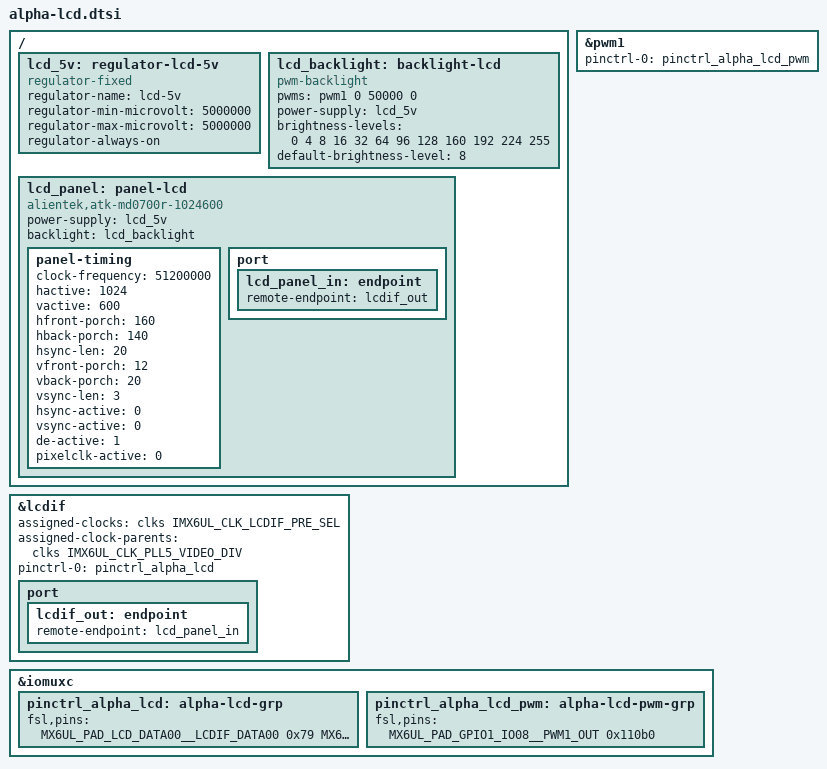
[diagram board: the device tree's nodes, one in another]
// SPDX-License-Identifier: GPL-2.0-or-later
/* ALPHA V2.4 + ATK-MD0700R-1024600, 24-bit RGB, DE mode. */
/ {
	lcd_5v: regulator-lcd-5v {
		compatible = "regulator-fixed";
		regulator-name = "lcd-5v";
		regulator-min-microvolt = <5000000>;
		regulator-max-microvolt = <5000000>;
		regulator-always-on;
	};

	lcd_backlight: backlight-lcd {
		compatible = "pwm-backlight";
		pwms = <&pwm1 0 50000 0>; /* 20 kHz, active high */
		power-supply = <&lcd_5v>;
		brightness-levels = <0 4 8 16 32 64 96 128 160 192 224 255>;
		default-brightness-level = <8>;
	};

	lcd_panel: panel-lcd {
		compatible = "alientek,atk-md0700r-1024600", "panel-dpi";
		power-supply = <&lcd_5v>;
		backlight = <&lcd_backlight>;
		/* Pin 40 is board RESET, not a separately controllable GPIO. */
		panel-timing {
			clock-frequency = <51200000>;
			hactive = <1024>;
			vactive = <600>;
			/* DE blanking totals: 320 pixels, 35 lines. */
			hfront-porch = <160>;
			hback-porch = <140>;
			hsync-len = <20>;
			vfront-porch = <12>;
			vback-porch = <20>;
			vsync-len = <3>;
			hsync-active = <0>;
			vsync-active = <0>;
			de-active = <1>;
			/* Drive on falling edge, panel samples rising edge. */
			pixelclk-active = <0>;
		};
		port {
			lcd_panel_in: endpoint {
				remote-endpoint = <&lcdif_out>;
			};
		};
	};
};

&lcdif {
	assigned-clocks = <&clks IMX6UL_CLK_LCDIF_PRE_SEL>;
	assigned-clock-parents = <&clks IMX6UL_CLK_PLL5_VIDEO_DIV>;
	pinctrl-names = "default";
	pinctrl-0 = <&pinctrl_alpha_lcd>;
	status = "okay";
	port {
		lcdif_out: endpoint {
			remote-endpoint = <&lcd_panel_in>;
		};
	};
};

&pwm1 {
	pinctrl-names = "default";
	pinctrl-0 = <&pinctrl_alpha_lcd_pwm>;
	status = "okay";
};

&iomuxc {
	pinctrl_alpha_lcd: alpha-lcd-grp {
		fsl,pins = <
			MX6UL_PAD_LCD_DATA00__LCDIF_DATA00 0x79
			MX6UL_PAD_LCD_DATA01__LCDIF_DATA01 0x79
			MX6UL_PAD_LCD_DATA02__LCDIF_DATA02 0x79
			MX6UL_PAD_LCD_DATA03__LCDIF_DATA03 0x79
			MX6UL_PAD_LCD_DATA04__LCDIF_DATA04 0x79
			MX6UL_PAD_LCD_DATA05__LCDIF_DATA05 0x79
			MX6UL_PAD_LCD_DATA06__LCDIF_DATA06 0x79
			MX6UL_PAD_LCD_DATA07__LCDIF_DATA07 0x79
			MX6UL_PAD_LCD_DATA08__LCDIF_DATA08 0x79
			MX6UL_PAD_LCD_DATA09__LCDIF_DATA09 0x79
			MX6UL_PAD_LCD_DATA10__LCDIF_DATA10 0x79
			MX6UL_PAD_LCD_DATA11__LCDIF_DATA11 0x79
			MX6UL_PAD_LCD_DATA12__LCDIF_DATA12 0x79
			MX6UL_PAD_LCD_DATA13__LCDIF_DATA13 0x79
			MX6UL_PAD_LCD_DATA14__LCDIF_DATA14 0x79
			MX6UL_PAD_LCD_DATA15__LCDIF_DATA15 0x79
			MX6UL_PAD_LCD_DATA16__LCDIF_DATA16 0x79
			MX6UL_PAD_LCD_DATA17__LCDIF_DATA17 0x79
			MX6UL_PAD_LCD_DATA18__LCDIF_DATA18 0x79
			MX6UL_PAD_LCD_DATA19__LCDIF_DATA19 0x79
			MX6UL_PAD_LCD_DATA20__LCDIF_DATA20 0x79
			MX6UL_PAD_LCD_DATA21__LCDIF_DATA21 0x79
			MX6UL_PAD_LCD_DATA22__LCDIF_DATA22 0x79
			MX6UL_PAD_LCD_DATA23__LCDIF_DATA23 0x79
			MX6UL_PAD_LCD_CLK__LCDIF_CLK 0x79
			MX6UL_PAD_LCD_ENABLE__LCDIF_ENABLE 0x79
			MX6UL_PAD_LCD_HSYNC__LCDIF_HSYNC 0x79
			MX6UL_PAD_LCD_VSYNC__LCDIF_VSYNC 0x79
		>;
	};
	pinctrl_alpha_lcd_pwm: alpha-lcd-pwm-grp {
		fsl,pins = <MX6UL_PAD_GPIO1_IO08__PWM1_OUT 0x110b0>;
	};
};
